AUTOSAR XML (schema 4.0)
standard types defined: float32, float64, sint16, sint32, sint8, uint16, uint32, uint8, void, boolean
package /ImplDataTypes
  impl type MultiStateBtnType: implementation-data-type=sint8, type-emitter=RTE
package /MappingSets
  data type mapping set MappingSet
package /PortInterfaces/ClientServer
  6 x client server interface:
    ppHeightMotor
    ppInclineMotor
    ppSlideMotor
    rpHeightMotor
    rpInclineMotor
    rpSlideMotor
package /PortInterfaces/SenderReceiver
  sender receiver interface ppSeatCtrlBtns
    data HeightBtnState: type=MultiStateBtnType
    data InclineBtnState: type=MultiStateBtnType
    data SlideBtnState: type=MultiStateBtnType
  sender receiver interface rpSeatCtrlBtns
    data HeightBtnState: type=MultiStateBtnType
    data InclineBtnState: type=MultiStateBtnType
    data SlideBtnState: type=MultiStateBtnType
  sender receiver interface rpSeatCtrlData
    data Height: type=uint8
    data Incline: type=uint8
    data Slide: type=uint8
package /SoftwareComponents
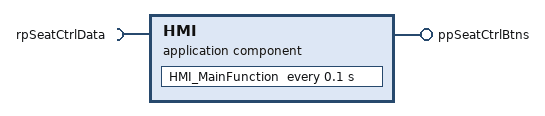
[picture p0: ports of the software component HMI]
  application sw component type HMI
    provide port ppSeatCtrlBtns: provided-interface=ppSeatCtrlBtns
    require port rpSeatCtrlData: required-interface=rpSeatCtrlData
    behavior Ibhv_HMI: data-type-mapping=MappingSet, handle-termination-and-restart=NO-SUPPORT
      timing event TE_HMI_MainFunction_100ms: start-on-event=HMI_MainFunction, period=0.1
      runnable HMI_MainFunction
        data-receive-point-by-arguments:
          access DRP_rpSeatCtrlData_Height: accessed-variable=rpSeatCtrlData.Height
          access DRP_rpSeatCtrlData_Incline: accessed-variable=rpSeatCtrlData.Incline
          access DRP_rpSeatCtrlData_Slide: accessed-variable=rpSeatCtrlData.Slide
        data-send-points:
          access DSP_ppSeatCtrlBtns_HeightBtnState: accessed-variable=ppSeatCtrlBtns.HeightBtnState
          access DSP_ppSeatCtrlBtns_InclineBtnState: accessed-variable=ppSeatCtrlBtns.InclineBtnState
          access DSP_ppSeatCtrlBtns_SlideBtnState: accessed-variable=ppSeatCtrlBtns.SlideBtnState
  application sw component type HeightMotor
    provide port pp_Hight_Motor: provided-interface=ppHeightMotor
    behavior Ibhv_HeightMotor: data-type-mapping=MappingSet, handle-termination-and-restart=NO-SUPPORT
  5 x swc implementation, all with programming-language=C, sw-version=1.0.0, vendor-id=255:
    Impl_HMI: behavior=Ibhv_HMI
      code-descriptors:
        code Code: artifact-descriptors=autosar-engineering-object={short-label=SWC.c, category=SWSRC}
      resource consumption ResourceConsumption
    Impl_HeightMotor: behavior=Ibhv_HeightMotor
      code-descriptors:
        code Code: artifact-descriptors=autosar-engineering-object={short-label=SWC.c, category=SWSRC}
      resource consumption ResourceConsumption
    Impl_InclineMotor: behavior=Ibhv_InclineMotor
      code-descriptors:
        code Code: artifact-descriptors=autosar-engineering-object={short-label=SWC.c, category=SWSRC}
      resource consumption ResourceConsumption
    Impl_SeatManager: behavior=Ibhv_SeatManager
      code-descriptors:
        code Code: artifact-descriptors=autosar-engineering-object={short-label=SWC.c, category=SWSRC}
      resource consumption ResourceConsumption
    Impl_SlideMotor: behavior=Ibhv_SlideMotor
      code-descriptors:
        code Code: artifact-descriptors=autosar-engineering-object={short-label=SWC.c, category=SWSRC}
      resource consumption ResourceConsumption
  application sw component type InclineMotor
    provide port pp_Incline_Motor: provided-interface=ppInclineMotor
    behavior Ibhv_InclineMotor: data-type-mapping=MappingSet, handle-termination-and-restart=NO-SUPPORT
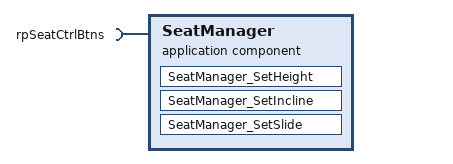
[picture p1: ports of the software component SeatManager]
  application sw component type SeatManager
    require port rpSeatCtrlBtns: required-interface=rpSeatCtrlBtns
    behavior Ibhv_SeatManager: data-type-mapping=MappingSet, handle-termination-and-restart=NO-SUPPORT
      data received event DRE_rpSeatCtrlBtns_HeightBtnState: start-on-event=SeatManager_SetHeight, data=rpSeatCtrlBtns.HeightBtnState
      data received event DRE_rpSeatCtrlBtns_InclineBtnState: start-on-event=SeatManager_SetSlide, data=rpSeatCtrlBtns.InclineBtnState
      data received event DRE_rpSeatCtrlBtns_SlideBtnState: start-on-event=SeatManager_SetIncline, data=rpSeatCtrlBtns.SlideBtnState
      runnable SeatManager_SetHeight
      runnable SeatManager_SetIncline
      runnable SeatManager_SetSlide
  application sw component type SlideMotor
    provide port pp_Slide_Motor: provided-interface=ppSlideMotor
    behavior Ibhv_SlideMotor: data-type-mapping=MappingSet, handle-termination-and-restart=NO-SUPPORT
package /Compositions
  composition sw component type sender_resceiver_comComposition
